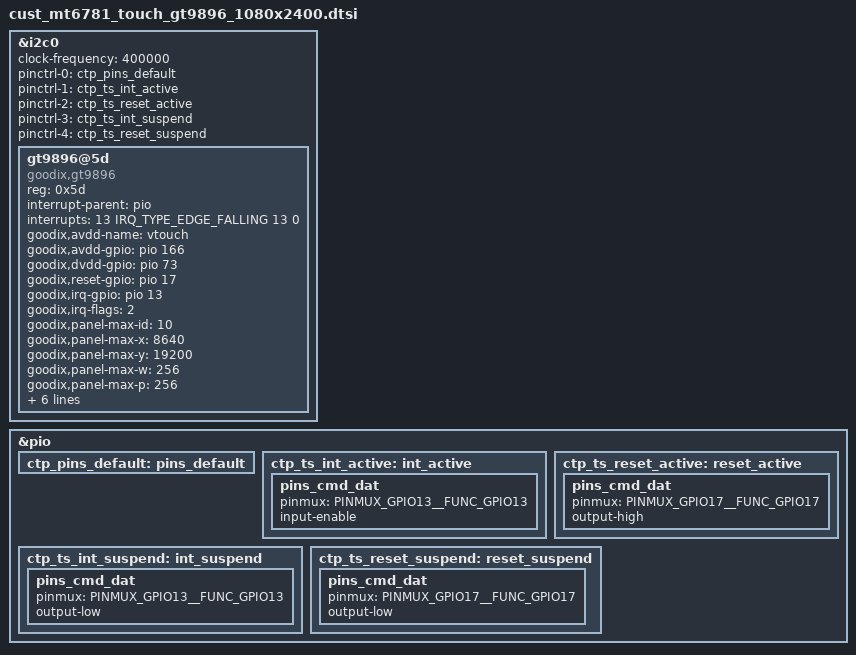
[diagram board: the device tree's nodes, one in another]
/*
 * Copyright (c) 2019 MediaTek Inc.
 *
 * This program is free software; you can redistribute it and/or modify
 * it under the terms of the GNU General Public License version 2 as
 * published by the Free Software Foundation.
 *
 * This program is distributed in the hope that it will be useful,
 * but WITHOUT ANY WARRANTY; without even the implied warranty of
 * MERCHANTABILITY or FITNESS FOR A PARTICULAR PURPOSE.  See the
 * GNU General Public License for more details.
 */
/* TOUCH start */
&i2c0 {
	clock-frequency = <400000>;
	pinctrl-names = "default", "ts_int_active",
		"ts_reset_active", "ts_int_suspend",
		"ts_reset_suspend";
	pinctrl-0 = <&ctp_pins_default>;
	pinctrl-1 = <&ctp_ts_int_active>;
	pinctrl-2 = <&ctp_ts_reset_active>;
	pinctrl-3 = <&ctp_ts_int_suspend>;
	pinctrl-4 = <&ctp_ts_reset_suspend>;

	gt9896@5d {
		compatible = "goodix,gt9896";
		reg = <0x5d>;
		interrupt-parent = <&pio>;
		interrupts = <13 IRQ_TYPE_EDGE_FALLING 13 0>;
		goodix,avdd-name = "vtouch";

		goodix,avdd-gpio = <&pio 166 0x0>;
		goodix,dvdd-gpio = <&pio 73 0x0>;
		goodix,reset-gpio = <&pio 17 0x0>;
		goodix,irq-gpio = <&pio 13 0x0>;
		goodix,irq-flags = <2>; /* 1:rising, 2:falling;*/
		goodix,panel-max-id = <10>;
		goodix,panel-max-x = <8640>;
		goodix,panel-max-y = <19200>;
		goodix,panel-max-w = <256>;
		goodix,panel-max-p = <256>;
		goodix,panel-key-map = <158 172 217>; /*BACK,HOMEPAGE,SEARCH*/
		tpd-filter-enable = <0>;
		tpd-filter-pixel-density = <161>;
		tpd-filter-custom-prameters = <0 0 0 0 0 0 0 0 0 0 0 0>;
		tpd-filter-custom-speed = <0 0 0>;
	};
};

&pio {
	ctp_pins_default: pins_default {
	};
	ctp_ts_int_active: int_active {
		pins_cmd_dat {
			pinmux = <PINMUX_GPIO13__FUNC_GPIO13>;
			input-enable;
		};
	};
	ctp_ts_reset_active: reset_active {
		pins_cmd_dat {
			pinmux = <PINMUX_GPIO17__FUNC_GPIO17>;
			output-high;
		};
	};
	ctp_ts_int_suspend: int_suspend {
		pins_cmd_dat {
			pinmux = <PINMUX_GPIO13__FUNC_GPIO13>;
			output-low;
		};
	};
	ctp_ts_reset_suspend: reset_suspend {
		pins_cmd_dat {
			pinmux = <PINMUX_GPIO17__FUNC_GPIO17>;
			output-low;
		};
	};
};

/* TOUCH end */
